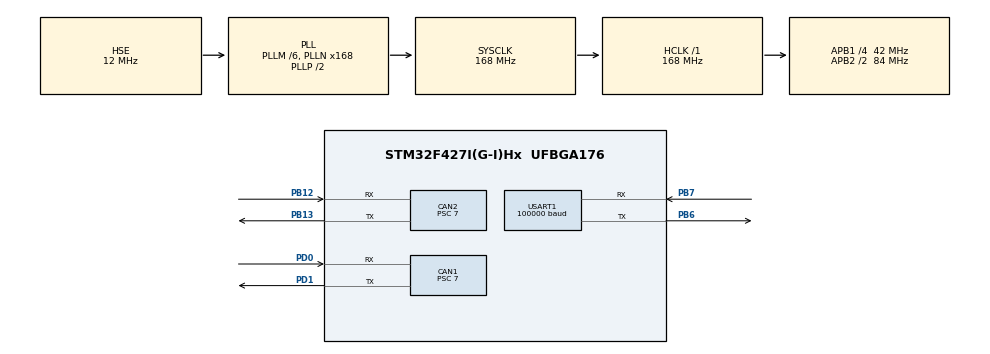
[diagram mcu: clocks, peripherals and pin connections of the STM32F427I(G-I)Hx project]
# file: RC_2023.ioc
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CAN1.ABOM=ENABLE
CAN1.AWUM=ENABLE
CAN1.BS1=CAN_BS1_4TQ
CAN1.CalculateBaudRate=999999
CAN1.CalculateTimeBit=1000
CAN1.CalculateTimeQuantum=166.66666666666669
CAN1.NART=ENABLE
CAN1.Prescaler=7
CAN2.ABOM=ENABLE
CAN2.AWUM=ENABLE
CAN2.BS1=CAN_BS1_4TQ
CAN2.CalculateBaudRate=999999
CAN2.CalculateTimeBit=1000
CAN2.CalculateTimeQuantum=166.66666666666669
CAN2.NART=ENABLE
CAN2.Prescaler=7
Dma.Request0=USART1_RX
Dma.USART1_RX.0.Direction=DMA_PERIPH_TO_MEMORY
Dma.USART1_RX.0.FIFOMode=DMA_FIFOMODE_DISABLE
Dma.USART1_RX.0.Instance=DMA2_Stream2
Dma.USART1_RX.0.MemDataAlignment=DMA_MDATAALIGN_BYTE
Dma.USART1_RX.0.MemInc=DMA_MINC_ENABLE
Dma.USART1_RX.0.Mode=DMA_CIRCULAR
Dma.USART1_RX.0.PeriphDataAlignment=DMA_PDATAALIGN_BYTE
Dma.USART1_RX.0.PeriphInc=DMA_PINC_DISABLE
Dma.USART1_RX.0.Priority=DMA_PRIORITY_LOW
FREERTOS.INCLUDE_vTaskDelayUntil=1
FREERTOS.Tasks01=defaultTask,0,128,StartDefaultTask,Default,NULL,Dynamic,NULL,NULL;Task_RobotContr,3,512,RobotControl,As external,NULL,Dynamic,NULL,NULL
Mcu.Family=STM32F4
Mcu.Name=STM32F427I(G-I)Hx
Mcu.Package=UFBGA176
NVIC.CAN1_RX0_IRQn=true\:5\:0\:true\:false\:true\:true\:true\:true\:true
NVIC.CAN2_RX0_IRQn=true\:6\:0\:true\:false\:true\:true\:true\:true\:true
NVIC.DMA2_Stream2_IRQn=true\:5\:0\:false\:false\:true\:true\:false\:true\:true
NVIC.PriorityGroup=NVIC_PRIORITYGROUP_4
NVIC.TIM1_UP_TIM10_IRQn=true\:15\:0\:true\:false\:true\:false\:false\:true\:true
NVIC.TimeBase=TIM1_UP_TIM10_IRQn
NVIC.TimeBaseIP=TIM1
NVIC.USART1_IRQn=true\:5\:0\:false\:false\:true\:true\:true\:true\:true
PA13.Mode=Serial_Wire
PA13.Signal=SYS_JTMS-SWDIO
PA14.Mode=Serial_Wire
PA14.Signal=SYS_JTCK-SWCLK
PB12.Mode=CAN_Activate
PB12.Signal=CAN2_RX
PB13.Mode=CAN_Activate
PB13.Signal=CAN2_TX
PB6.GPIO_PuPd=GPIO_PULLUP
PB6.Mode=Asynchronous
PB6.Signal=USART1_TX
PB7.GPIO_PuPd=GPIO_PULLUP
PB7.Mode=Asynchronous
PB7.Signal=USART1_RX
PD0.Mode=CAN_Activate
PD0.Signal=CAN1_RX
PD1.Mode=CAN_Activate
PD1.Signal=CAN1_TX
PH0/OSC_IN.Mode=HSE-External-Oscillator
PH0/OSC_IN.Signal=RCC_OSC_IN
PH1/OSC_OUT.Mode=HSE-External-Oscillator
PH1/OSC_OUT.Signal=RCC_OSC_OUT
ProjectManager.HeapSize=0x200
ProjectManager.StackSize=0x400
ProjectManager.TargetToolchain=MDK-ARM V5.32
RCC.48MHZClocksFreq_Value=84000000
RCC.AHBFreq_Value=168000000
RCC.APB1CLKDivider=RCC_HCLK_DIV4
RCC.APB1Freq_Value=42000000
RCC.APB1TimFreq_Value=84000000
RCC.APB2CLKDivider=RCC_HCLK_DIV2
RCC.APB2Freq_Value=84000000
RCC.APB2TimFreq_Value=168000000
RCC.CortexFreq_Value=168000000
RCC.HCLKFreq_Value=168000000
RCC.HSE_VALUE=12000000
RCC.HSI_VALUE=16000000
RCC.LSE_VALUE=32768
RCC.PLLM=6
RCC.PLLN=168
RCC.PLLSourceVirtual=RCC_PLLSOURCE_HSE
RCC.SYSCLKFreq_VALUE=168000000
RCC.SYSCLKSource=RCC_SYSCLKSOURCE_PLLCLK
RCC.VCOOutputFreq_Value=336000000
USART1.BaudRate=100000
USART1.Parity=PARITY_EVEN
USART1.VirtualMode=VM_ASYNC
VP_FREERTOS_VS_CMSIS_V1.Mode=CMSIS_V1
VP_SYS_VS_tim1.Mode=TIM1
board=custom

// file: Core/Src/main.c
/* USER CODE BEGIN Header */
/**
  ******************************************************************************
  * @file           : main.c
  * @brief          : Main program body
  ******************************************************************************
  * @attention
  *
  * Copyright (c) 2023 STMicroelectronics.
  * All rights reserved.
  *
  * This software is licensed under terms that can be found in the LICENSE file
  * in the root directory of this software component.
  * If no LICENSE file comes with this software, it is provided AS-IS.
  *
  ******************************************************************************
  */
/* USER CODE END Header */
#include "main.h"
#include "cmsis_os.h"
#include "can.h"
#include "dma.h"
#include "usart.h"
#include "gpio.h"

/* USER CODE BEGIN Includes */
#include "Can_Control.h"
#include "bsp_usart.h"
/* USER CODE END Includes */

void SystemClock_Config(void);
void MX_FREERTOS_Init(void);

int main(void)
{

  /* MCU Configuration--------------------------------------------------------*/

  /* Reset of all peripherals, Initializes the Flash interface and the Systick. */
  HAL_Init();

  /* Configure the system clock */
  SystemClock_Config();

  /* Initialize all configured peripherals */
  MX_GPIO_Init();
  MX_DMA_Init();
  MX_CAN1_Init();
  MX_CAN2_Init();
  MX_USART1_UART_Init();
  /* USER CODE BEGIN 2 */
  CAN_IT_Init(&hcan1, 1);//过滤器初始化
  CAN_IT_Init(&hcan2, 2);//过滤器初始化
	HAL_UART_Receive_IT_IDLE(&huart1,UART_Buffer,100);   //启动串口接收
  /* USER CODE END 2 */

  /* Call init function for freertos objects (in freertos.c) */
  MX_FREERTOS_Init();

  /* Start scheduler */
  osKernelStart();
  /* We should never get here as control is now taken by the scheduler */
  /* Infinite loop */
  while (1)
  {

  }
}

void SystemClock_Config(void)
{
  RCC_OscInitTypeDef RCC_OscInitStruct = {0};
  RCC_ClkInitTypeDef RCC_ClkInitStruct = {0};

  /** Configure the main internal regulator output voltage
  */
  __HAL_RCC_PWR_CLK_ENABLE();
  __HAL_PWR_VOLTAGESCALING_CONFIG(PWR_REGULATOR_VOLTAGE_SCALE1);

  /** Initializes the RCC Oscillators according to the specified parameters
  * in the RCC_OscInitTypeDef structure.
  */
  RCC_OscInitStruct.OscillatorType = RCC_OSCILLATORTYPE_HSE;
  RCC_OscInitStruct.HSEState = RCC_HSE_ON;
  RCC_OscInitStruct.PLL.PLLState = RCC_PLL_ON;
  RCC_OscInitStruct.PLL.PLLSource = RCC_PLLSOURCE_HSE;
  RCC_OscInitStruct.PLL.PLLM = 6;
  RCC_OscInitStruct.PLL.PLLN = 168;
  RCC_OscInitStruct.PLL.PLLP = RCC_PLLP_DIV2;
  RCC_OscInitStruct.PLL.PLLQ = 4;
  if (HAL_RCC_OscConfig(&RCC_OscInitStruct) != HAL_OK)
  {
    Error_Handler();
  }

  /** Initializes the CPU, AHB and APB buses clocks
  */
  RCC_ClkInitStruct.ClockType = RCC_CLOCKTYPE_HCLK|RCC_CLOCKTYPE_SYSCLK
                              |RCC_CLOCKTYPE_PCLK1|RCC_CLOCKTYPE_PCLK2;
  RCC_ClkInitStruct.SYSCLKSource = RCC_SYSCLKSOURCE_PLLCLK;
  RCC_ClkInitStruct.AHBCLKDivider = RCC_SYSCLK_DIV1;
  RCC_ClkInitStruct.APB1CLKDivider = RCC_HCLK_DIV4;
  RCC_ClkInitStruct.APB2CLKDivider = RCC_HCLK_DIV2;

  if (HAL_RCC_ClockConfig(&RCC_ClkInitStruct, FLASH_LATENCY_5) != HAL_OK)
  {
    Error_Handler();
  }
}

void HAL_TIM_PeriodElapsedCallback(TIM_HandleTypeDef *htim)
{
  if (htim->Instance == TIM1) {
    HAL_IncTick();
  }
}

void Error_Handler(void)
{
  __disable_irq();
  while (1)
  {
  }
}

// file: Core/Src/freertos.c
/* USER CODE BEGIN Header */
/**
  ******************************************************************************
  * File Name          : freertos.c
  * Description        : Code for freertos applications
  ******************************************************************************
  * @attention
  *
  * Copyright (c) 2023 STMicroelectronics.
  * All rights reserved.
  *
  * This software is licensed under terms that can be found in the LICENSE file
  * in the root directory of this software component.
  * If no LICENSE file comes with this software, it is provided AS-IS.
  *
  ******************************************************************************
  */
/* USER CODE END Header */

#include "FreeRTOS.h"
#include "task.h"
#include "main.h"
#include "cmsis_os.h"

osThreadId defaultTaskHandle;
osThreadId Task_RobotContrHandle;

void StartDefaultTask(void const * argument);
extern void RobotControl(void const * argument);

void MX_FREERTOS_Init(void); /* (MISRA C 2004 rule 8.1) */

/* GetIdleTaskMemory prototype (linked to static allocation support) */
void vApplicationGetIdleTaskMemory( StaticTask_t **ppxIdleTaskTCBBuffer, StackType_t **ppxIdleTaskStackBuffer, uint32_t *pulIdleTaskStackSize );

/* USER CODE BEGIN GET_IDLE_TASK_MEMORY */
static StaticTask_t xIdleTaskTCBBuffer;
static StackType_t xIdleStack[configMINIMAL_STACK_SIZE];

void vApplicationGetIdleTaskMemory( StaticTask_t **ppxIdleTaskTCBBuffer, StackType_t **ppxIdleTaskStackBuffer, uint32_t *pulIdleTaskStackSize )
{
  *ppxIdleTaskTCBBuffer = &xIdleTaskTCBBuffer;
  *ppxIdleTaskStackBuffer = &xIdleStack[0];
  *pulIdleTaskStackSize = configMINIMAL_STACK_SIZE;
  /* place for user code */
}
/* USER CODE END GET_IDLE_TASK_MEMORY */

void MX_FREERTOS_Init(void) {

  /* Create the thread(s) */
  /* definition and creation of defaultTask */
  osThreadDef(defaultTask, StartDefaultTask, osPriorityNormal, 0, 128);
  defaultTaskHandle = osThreadCreate(osThread(defaultTask), NULL);

  /* definition and creation of Task_RobotContr */
  osThreadDef(Task_RobotContr, RobotControl, osPriorityRealtime, 0, 512);
  Task_RobotContrHandle = osThreadCreate(osThread(Task_RobotContr), NULL);

}

void StartDefaultTask(void const * argument)
{
  for(;;)
  {
    osDelay(1);
  }
}
